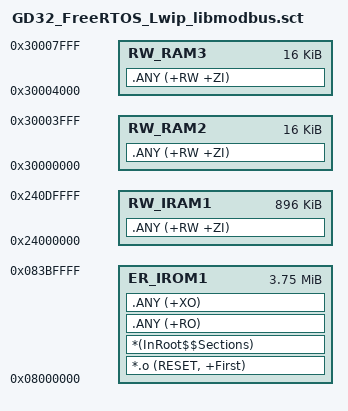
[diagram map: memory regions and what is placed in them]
; *************************************************************
; *** Scatter-Loading Description File generated by uVision ***
; *************************************************************

LR_IROM1 0x08000000 0x003C0000  {    ; load region size_region
  ER_IROM1 0x08000000 0x003C0000  {  ; load address = execution address
   *.o (RESET, +First)
   *(InRoot$$Sections)
   .ANY (+RO)
   .ANY (+XO)
  }
  RW_RAM2 0x30000000 0x00004000  {  ; RW data
   .ANY (+RW +ZI)
  }
  RW_RAM3 0x30004000 0x00004000  {
   .ANY (+RW +ZI)
  }
  RW_IRAM1 0x24000000 0x000E0000  {
   .ANY (+RW +ZI)
  }
}

